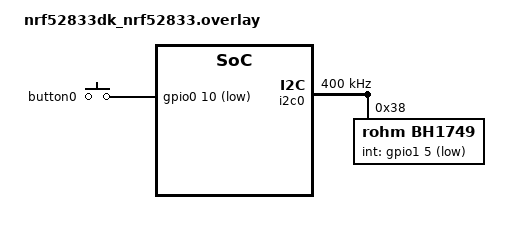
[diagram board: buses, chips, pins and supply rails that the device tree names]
// To get started, press Ctrl+Space (or Option+Esc) to bring up the completion menu and view the available nodes.

// You can also use the buttons in the sidebar to perform actions on nodes.
// Actions currently available include:

// * Enabling / disabling the node
// * Adding the bus to a bus
// * Removing the node
// * Connecting ADC channels

// For more help, browse the DeviceTree documentation at https://docs.zephyrproject.org/latest/guides/dts/index.html
// You can also visit the nRF DeviceTree extension documentation at https://docs.nordicsemi.com/bundle/nrf-connect-vscode/page/guides/ncs_configure_app.html#devicetree-support-in-the-extension

&i2c0_default {
	group1 {
		psels = <NRF_PSEL(TWIM_SDA, 0, 11)>, <NRF_PSEL(TWIM_SCL, 1, 9)>;
	};
};

&i2c0_sleep {
	group1 {
		psels = <NRF_PSEL(TWIM_SDA, 0, 11)>, <NRF_PSEL(TWIM_SCL, 1, 9)>;
	};
};

&button0 {
	gpios = <&gpio0 10 (GPIO_ACTIVE_LOW | GPIO_PULL_UP)>;
};

&i2c0 {
	compatible = "nordic,nrf-twim";
	status = "okay";
	clock-frequency = <I2C_BITRATE_FAST>;

	pinctrl-0 = <&i2c0_default>;
	pinctrl-1 = <&i2c0_sleep>;
	pinctrl-names = "default", "sleep";
	
	bh1749: bh1749@38 {
		compatible = "rohm,bh1749";
		reg = <0x38>;
		int-gpios = <&gpio1 5 (GPIO_PULL_UP | GPIO_ACTIVE_LOW)>;
	};
};
